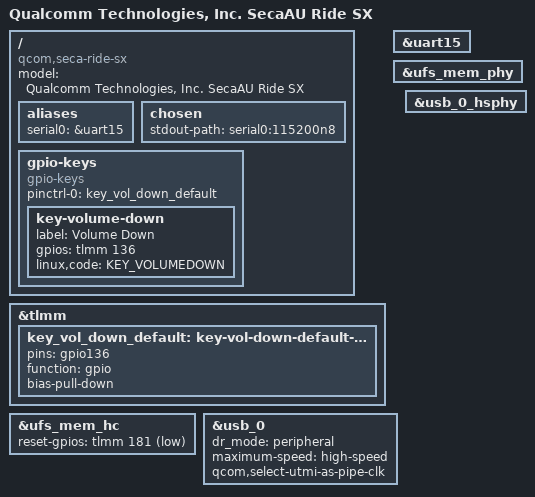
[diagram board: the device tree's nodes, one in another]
// SPDX-License-Identifier: BSD-3-Clause
/*
 * Copyright (c) Qualcomm Technologies, Inc. and/or its subsidiaries.
 *
 * SecaAU Ride SX, local U-Boot devicetree (see seca.dtsi).
 */

/dts-v1/;

#include <dt-bindings/input/linux-event-codes.h>
#include "seca.dtsi"

/ {
	model = "Qualcomm Technologies, Inc. SecaAU Ride SX";
	compatible = "qcom,seca-ride-sx", "qcom,seca";

	aliases {
		serial0 = &uart15;
	};

	chosen {
		stdout-path = "serial0:115200n8";
	};

	gpio-keys {
		compatible = "gpio-keys";

		pinctrl-0 = <&key_vol_down_default>;
		pinctrl-names = "default";

		key-volume-down {
			label = "Volume Down";
			gpios = <&tlmm 136 GPIO_ACTIVE_HIGH>;
			linux,code = <KEY_VOLUMEDOWN>;
		};
	};
};

&tlmm {
	key_vol_down_default: key-vol-down-default-state {
		pins = "gpio136";
		function = "gpio";
		bias-pull-down;
	};
};

&uart15 {
	status = "okay";
};

&ufs_mem_hc {
	reset-gpios = <&tlmm 181 GPIO_ACTIVE_LOW>;

	status = "okay";
};

&ufs_mem_phy {
	status = "okay";
};

&usb_0 {
	dr_mode = "peripheral";
	maximum-speed = "high-speed";
	qcom,select-utmi-as-pipe-clk;

	status = "okay";
};

&usb_0_hsphy {
	status = "okay";
};
